# PIC32MM0016GPL036 register map
Vendor: Microchip
Registers are 32-bit, read-write, reset 0x0 unless marked. A register's access mark holds for its fields unless they carry their own. Addresses are absolute, and some are shared; only a register's first bit layout is shown; [hi:lo] are bit positions; {n}, {i} and the like mark numbered series.

## PORTA
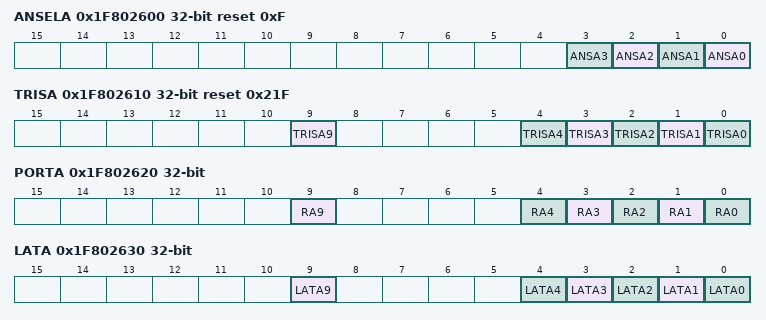
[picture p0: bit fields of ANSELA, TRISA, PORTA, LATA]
0x1F802600 ANSELA reset 0xF
  [n] ANSA{n} (n=0..3)
0x1F802610 TRISA reset 0x21F
  [9] TRISA9, [n] TRISA{n} (n=0..4)
0x1F802620 PORTA reset not defined — (power-on value ----------------------x----xxxxx)
  [9] RA9, [n] RA{n} (n=0..4)
0x1F802630 LATA
  [9] LATA9, [n] LATA{n} (n=0..4)
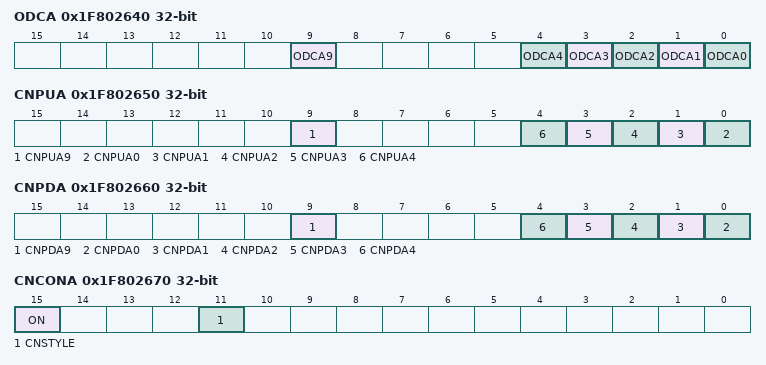
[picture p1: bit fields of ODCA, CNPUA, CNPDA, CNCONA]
0x1F802640 ODCA
  [9] ODCA9, [n] ODCA{n} (n=0..4)
0x1F802650 CNPUA
  [9] CNPUA9, [n] CNPUA{n} (n=0..4)
0x1F802660 CNPDA
  [9] CNPDA9, [n] CNPDA{n} (n=0..4)
0x1F802670 CNCONA
  [15] ON, [11] CNSTYLE
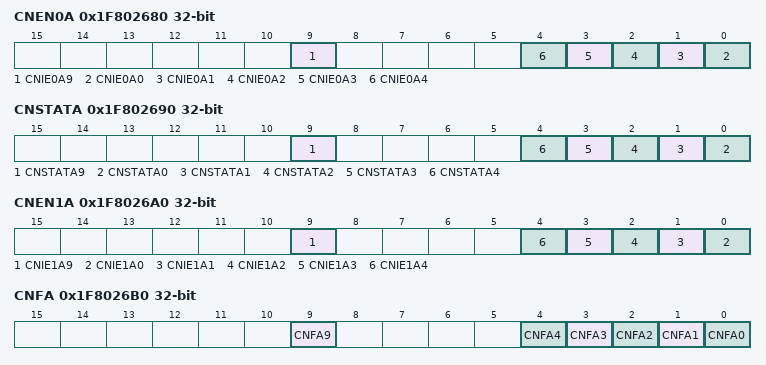
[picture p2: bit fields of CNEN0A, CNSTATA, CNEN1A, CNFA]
0x1F802680 CNEN0A
  [9] CNIE0A9, [n] CNIE0A{n} (n=0..4)
0x1F802690 CNSTATA reset not defined — (power-on value ----------------------x----xxxxx)
  [9] CNSTATA9, [n] CNSTATA{n} (n=0..4)
0x1F8026A0 CNEN1A
  [9] CNIE1A9, [n] CNIE1A{n} (n=0..4)
0x1F8026B0 CNFA
  [9] CNFA9, [n] CNFA{n} (n=0..4)

## PORTB
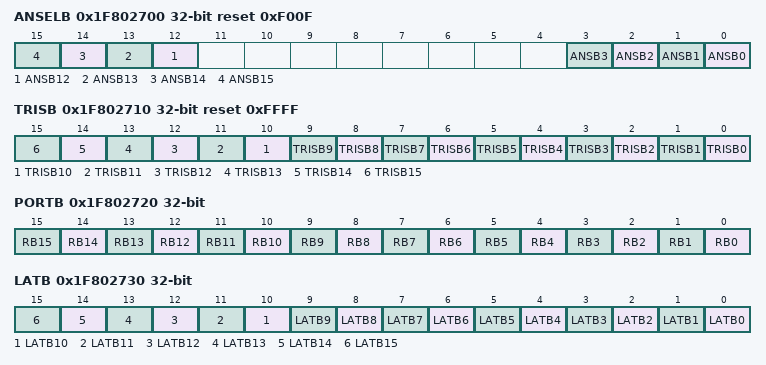
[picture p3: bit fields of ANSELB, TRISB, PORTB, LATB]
0x1F802700 ANSELB reset 0xF00F
  [n] ANSB{n} (n=12..15), [n] ANSB{n} (n=0..3)
0x1F802710 TRISB reset 0xFFFF
  [n] TRISB{n} (n=0..15)
0x1F802720 PORTB reset not defined — (power-on value ----------------xxxxxxxxxxxxxxxx)
  [n] RB{n} (n=0..15)
0x1F802730 LATB
  [n] LATB{n} (n=0..15)
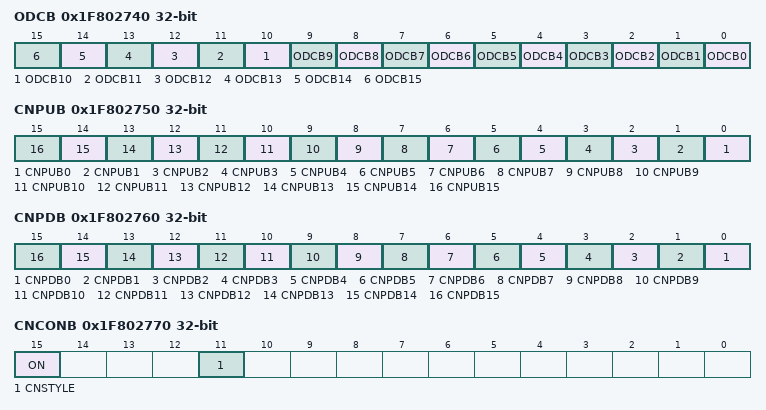
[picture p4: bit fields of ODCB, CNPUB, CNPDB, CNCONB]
0x1F802740 ODCB
  [n] ODCB{n} (n=0..15)
0x1F802750 CNPUB
  [n] CNPUB{n} (n=0..15)
0x1F802760 CNPDB
  [n] CNPDB{n} (n=0..15)
0x1F802770 CNCONB
  [15] ON, [11] CNSTYLE
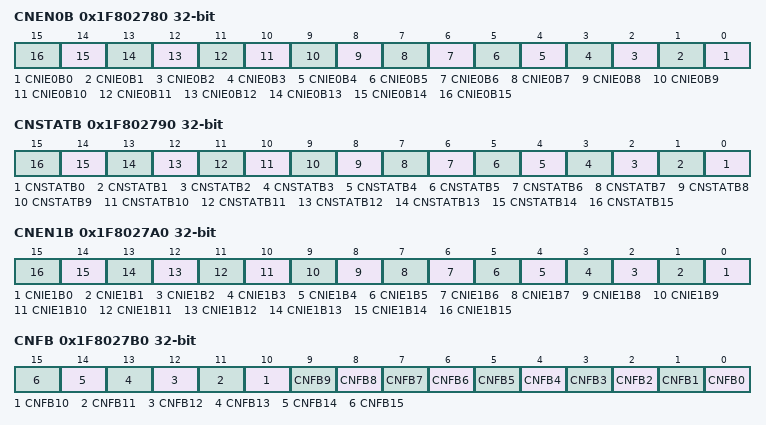
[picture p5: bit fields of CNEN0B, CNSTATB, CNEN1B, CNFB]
0x1F802780 CNEN0B
  [n] CNIE0B{n} (n=0..15)
0x1F802790 CNSTATB reset not defined — (power-on value ----------------xxxxxxxxxxxxxxxx)
  [n] CNSTATB{n} (n=0..15)
0x1F8027A0 CNEN1B
  [n] CNIE1B{n} (n=0..15)
0x1F8027B0 CNFB
  [n] CNFB{n} (n=0..15)

## PORTC
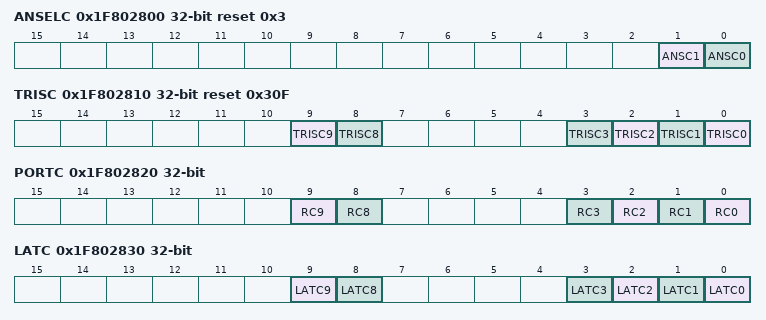
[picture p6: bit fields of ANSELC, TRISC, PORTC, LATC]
0x1F802800 ANSELC reset 0x3
  [1] ANSC1, [0] ANSC0
0x1F802810 TRISC reset 0x30F
  [9] TRISC9, [8] TRISC8, [n] TRISC{n} (n=0..3)
0x1F802820 PORTC reset not defined — (power-on value ----------------------xx----xxxx)
  [9] RC9, [8] RC8, [n] RC{n} (n=0..3)
0x1F802830 LATC
  [9] LATC9, [8] LATC8, [n] LATC{n} (n=0..3)
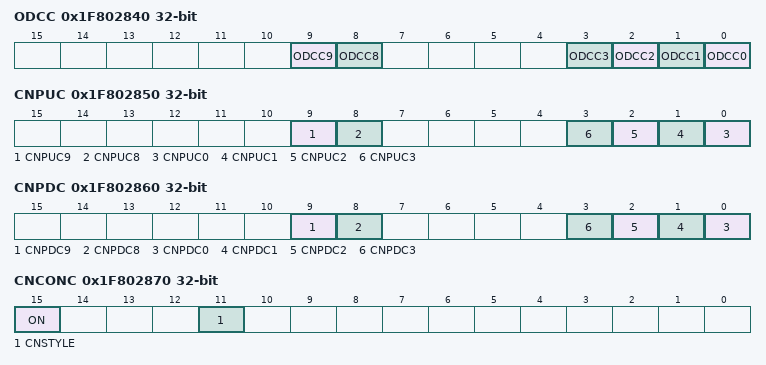
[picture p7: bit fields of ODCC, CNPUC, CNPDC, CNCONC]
0x1F802840 ODCC
  [9] ODCC9, [8] ODCC8, [n] ODCC{n} (n=0..3)
0x1F802850 CNPUC
  [9] CNPUC9, [8] CNPUC8, [n] CNPUC{n} (n=0..3)
0x1F802860 CNPDC
  [9] CNPDC9, [8] CNPDC8, [n] CNPDC{n} (n=0..3)
0x1F802870 CNCONC
  [15] ON, [11] CNSTYLE
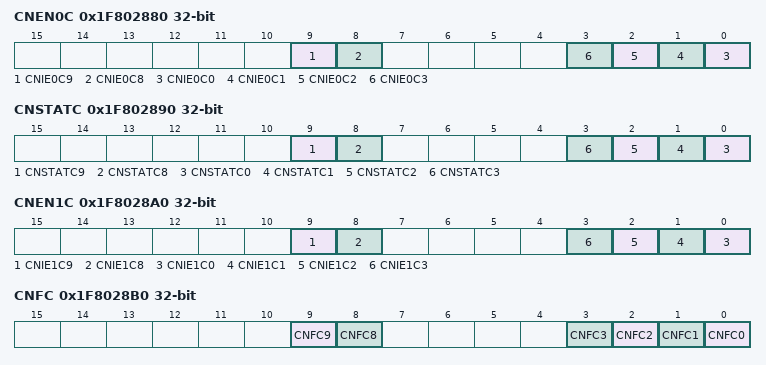
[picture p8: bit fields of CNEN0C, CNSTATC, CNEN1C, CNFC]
0x1F802880 CNEN0C
  [9] CNIE0C9, [8] CNIE0C8, [n] CNIE0C{n} (n=0..3)
0x1F802890 CNSTATC reset not defined — (power-on value ----------------------xx----xxxx)
  [9] CNSTATC9, [8] CNSTATC8, [n] CNSTATC{n} (n=0..3)
0x1F8028A0 CNEN1C
  [9] CNIE1C9, [8] CNIE1C8, [n] CNIE1C{n} (n=0..3)
0x1F8028B0 CNFC
  [9] CNFC9, [8] CNFC8, [n] CNFC{n} (n=0..3)

## WDT
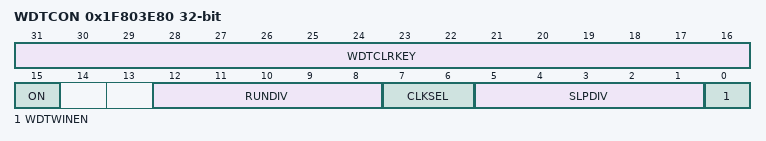
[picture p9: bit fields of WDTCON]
0x1F803E80 WDTCON reset not defined — (power-on value 0000000000000000x--xxxxxxxxxxxx0)
  [31:16] WDTCLRKEY wo, [15] ON, [12:8] RUNDIV ro, [7:6] CLKSEL ro, [5:1] SLPDIV ro, [0] WDTWINEN

## TMR1
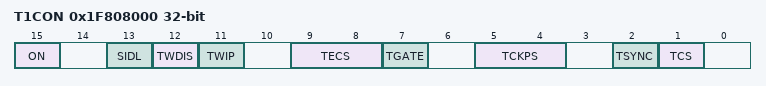
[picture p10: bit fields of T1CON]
0x1F808000 T1CON
  [15] ON, [13] SIDL, [12] TWDIS, [11] TWIP, [9:8] TECS, [7] TGATE, [5:4] TCKPS, [2] TSYNC, [1] TCS
0x1F808010 TMR1
0x1F808020 PR1 reset 0xFFFF

## SPI1
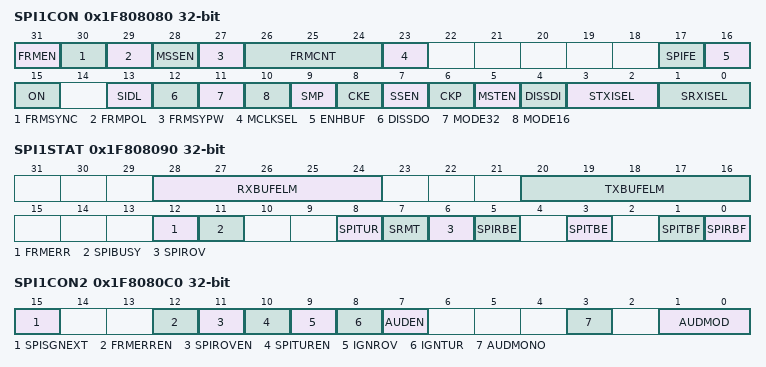
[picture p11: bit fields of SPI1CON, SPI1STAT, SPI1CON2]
0x1F808080 SPI1CON reset not defined — (power-on value 00000000x-----0000000000000x0000)
  [31] FRMEN, [30] FRMSYNC, [29] FRMPOL, [28] MSSEN, [27] FRMSYPW, [26:24] FRMCNT, [23] MCLKSEL, [17] SPIFE, [16] ENHBUF, [15] ON, [13] SIDL, [12] DISSDO, [11] MODE32, [10] MODE16, [9] SMP, [8] CKE, [7] SSEN, [6] CKP, [5] MSTEN, [4] DISSDI, [3:2] STXISEL, [1:0] SRXISEL
0x1F808090 SPI1STAT reset not defined — (power-on value ---00000---00000---x0--0000-0-00)
  [28:24] RXBUFELM ro, [20:16] TXBUFELM ro, [12] FRMERR, [11] SPIBUSY ro, [8] SPITUR ro, [7] SRMT ro, [6] SPIROV ro, [5] SPIRBE ro, [3] SPITBE ro, [1] SPITBF ro, [0] SPIRBF ro
0x1F8080A0 SPI1BUF reset not defined — (power-on value xxxxxxxxxxxxxxxxxxxxxxxxxxxxxxxx)
0x1F8080B0 SPI1BRG reset not defined — (power-on value -------------------xxxxxxxxxxxxx)
  [12:0] SPI1BRG
0x1F8080C0 SPI1CON2 reset not defined — (power-on value ----------------x--xxxxxx---x-xx)
  [15] SPISGNEXT, [12] FRMERREN, [11] SPIROVEN, [10] SPITUREN, [9] IGNROV, [8] IGNTUR, [7] AUDEN, [3] AUDMONO, [1:0] AUDMOD

## SPI2
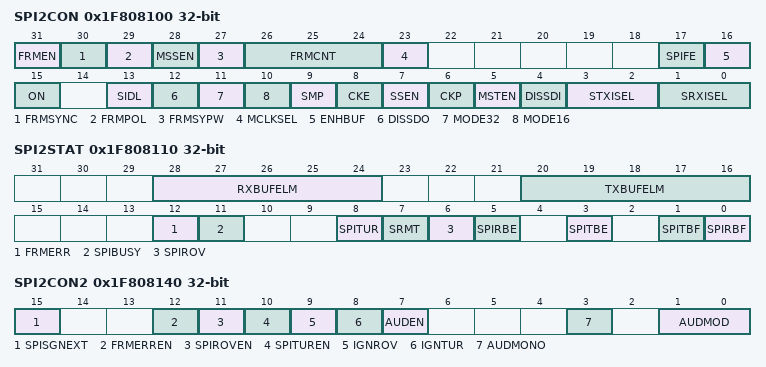
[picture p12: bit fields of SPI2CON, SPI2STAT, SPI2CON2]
0x1F808100 SPI2CON reset not defined — (power-on value 00000000x-----0000000000000x0000)
  [31] FRMEN, [30] FRMSYNC, [29] FRMPOL, [28] MSSEN, [27] FRMSYPW, [26:24] FRMCNT, [23] MCLKSEL, [17] SPIFE, [16] ENHBUF, [15] ON, [13] SIDL, [12] DISSDO, [11] MODE32, [10] MODE16, [9] SMP, [8] CKE, [7] SSEN, [6] CKP, [5] MSTEN, [4] DISSDI, [3:2] STXISEL, [1:0] SRXISEL
0x1F808110 SPI2STAT reset not defined — (power-on value ---00000---00000---x0--0000-0-00)
  [28:24] RXBUFELM ro, [20:16] TXBUFELM ro, [12] FRMERR, [11] SPIBUSY ro, [8] SPITUR ro, [7] SRMT ro, [6] SPIROV ro, [5] SPIRBE ro, [3] SPITBE ro, [1] SPITBF ro, [0] SPIRBF ro
0x1F808120 SPI2BUF reset not defined — (power-on value xxxxxxxxxxxxxxxxxxxxxxxxxxxxxxxx)
0x1F808130 SPI2BRG reset not defined — (power-on value -------------------xxxxxxxxxxxxx)
  [12:0] SPI2BRG
0x1F808140 SPI2CON2 reset not defined — (power-on value ----------------x--xxxxxx---x-xx)
  [15] SPISGNEXT, [12] FRMERREN, [11] SPIROVEN, [10] SPITUREN, [9] IGNROV, [8] IGNTUR, [7] AUDEN, [3] AUDMONO, [1:0] AUDMOD

## SABE_UDID
{0x1FC4183C+4i} UDID{i} ro reset not defined (i=1..5)
